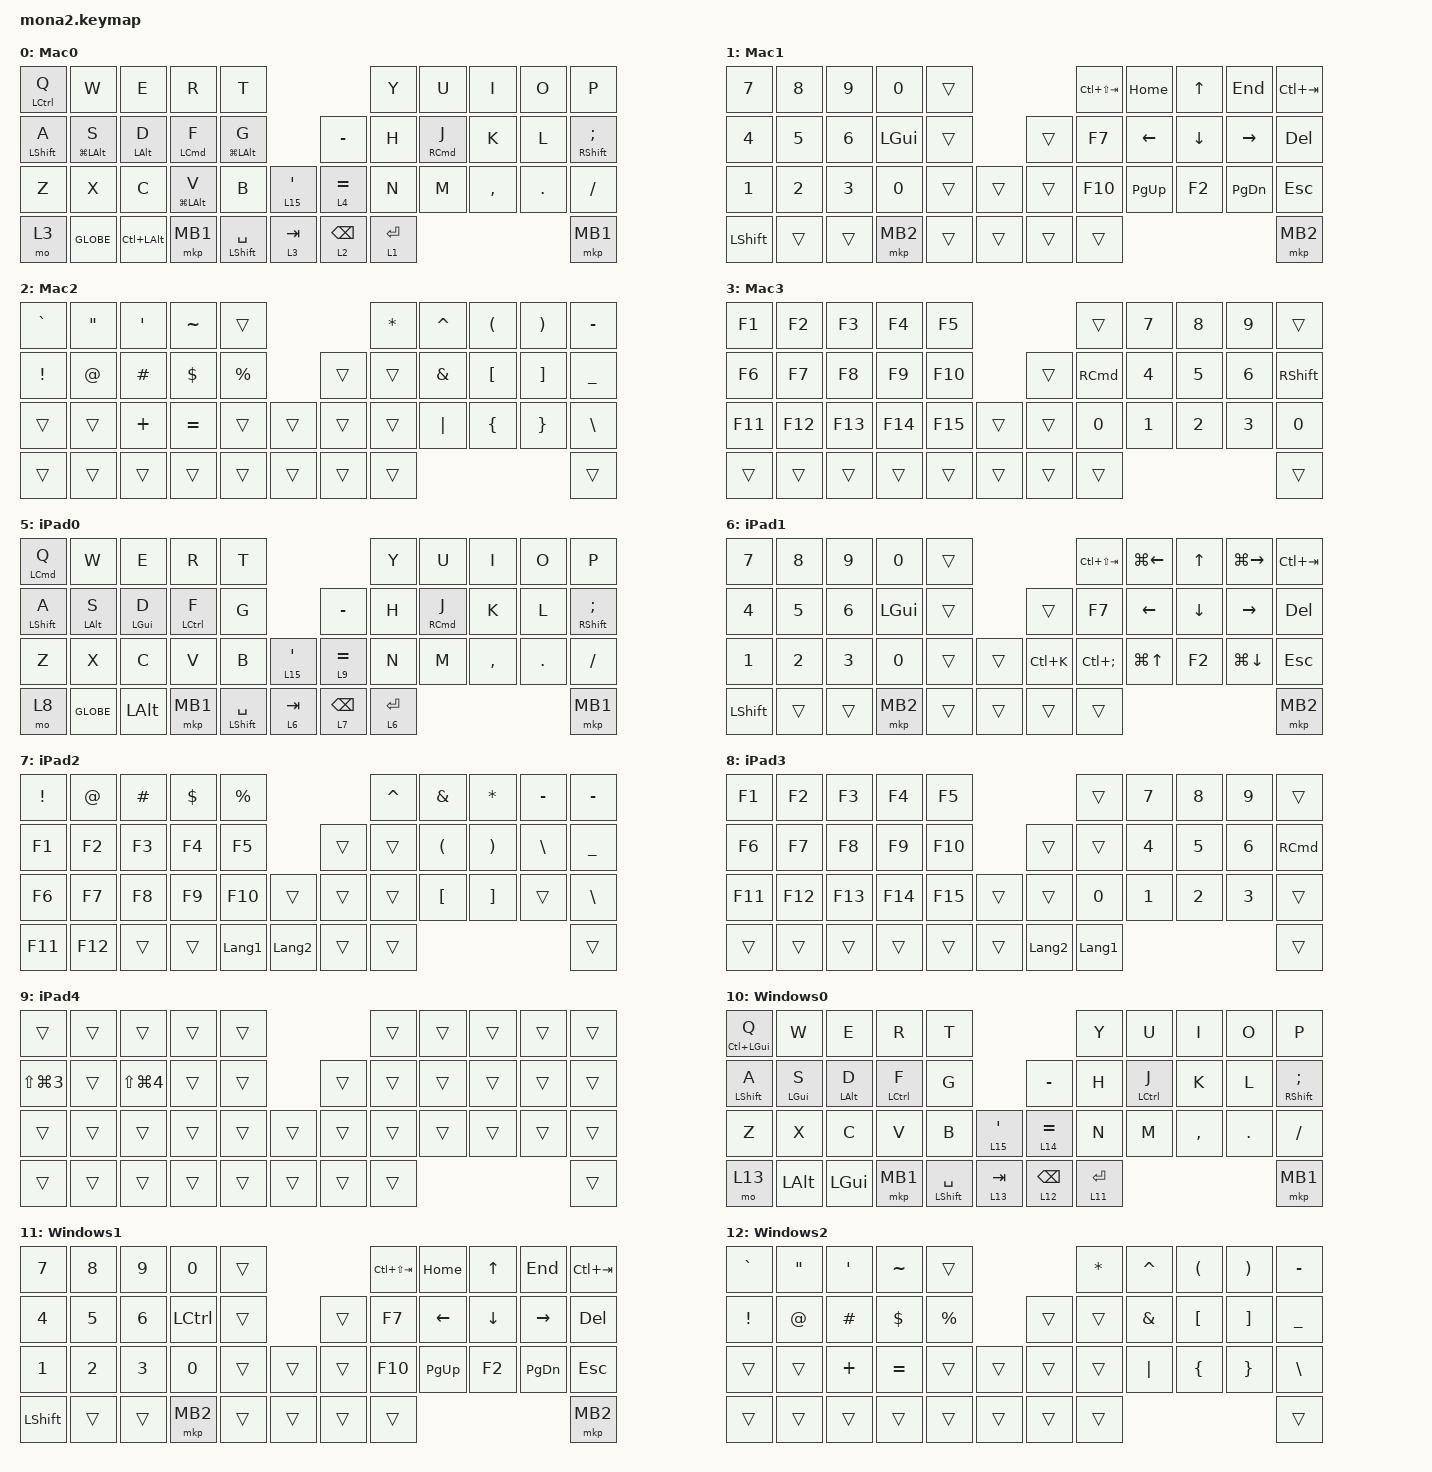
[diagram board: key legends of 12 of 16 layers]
#include <input/processors.dtsi>
#include <dt-bindings/zmk/input_transform.h>
#include <zephyr/dt-bindings/input/input-event-codes.h>

#define ZMK_POINTING_DEFAULT_SCRL_VAL 80

#include <behaviors.dtsi>
#include <dt-bindings/zmk/bt.h>
#include <dt-bindings/zmk/keys.h>
#include <dt-bindings/zmk/pointing.h>

#define MOUSE 6
#define SCROLL 7

&mt {
    flavor = "balanced";
    quick-tap-ms = <200>;
    tapping-term-ms = <180>;
    require-prior-idle-ms = <150>;
};

&lt {
    quick-tap-ms = <175>;
    tapping-term-ms = <165>;
};

/ {
    combos {
        compatible = "zmk,combos";

        alt_f4 {
            bindings = <&kp RA(F4)>;
            key-positions = <10 20>;
            timeout-ms = <201>;
            layers = <10>;
        };

        kana {
            bindings = <&kp LANG1>;
            key-positions = <17 18>;
            timeout-ms = <201>;
            layers = <10 0 5>;
        };

        ABC {
            bindings = <&kp LANG2>;
            key-positions = <13 12>;
            layers = <0 5 10>;
            timeout-ms = <201>;
        };
    };

    macros {
        to_layer_0: to_layer_0 {
            compatible = "zmk,behavior-macro-one-param";
            #binding-cells = <1>;
            bindings = <&to 0 &macro_param_1to1 &kp MACRO_PLACEHOLDER>;
            label = "TO_LAYER_0";
        };

        Bluetooth0: Bluetooth0 {
            compatible = "zmk,behavior-macro";
            #binding-cells = <0>;
            bindings =
                <&bt BT_SEL 0 &to 0 &bt BT_DISC 1 &bt BT_DISC 2 &bt BT_DISC 3 &bt BT_DISC 4>,
                <&macro_press>;

            label = "BLUETOOTH0";
        };

        Bluetooth1: Bluetooth1 {
            compatible = "zmk,behavior-macro";
            #binding-cells = <0>;
            bindings =
                <&bt BT_SEL 1 &to 5 &bt BT_DISC 0 &bt BT_DISC 2 &bt BT_DISC 3 &bt BT_DISC 4>,
                <&macro_press>;

            label = "BLUETOOTH1";
        };

        Bluetooth2: Bluetooth2 {
            compatible = "zmk,behavior-macro";
            #binding-cells = <0>;
            bindings =
                <&bt BT_SEL 2 &to 10 &bt BT_DISC 0 &bt BT_DISC 1 &bt BT_DISC 3 &bt BT_DISC 4>,
                <&macro_press>;

            label = "BLUETOOTH2";
        };

        Bluetooth3: Bluetooth3 {
            compatible = "zmk,behavior-macro";
            #binding-cells = <0>;
            bindings =
                <&bt BT_SEL 3 &to 10 &bt BT_DISC 0 &bt BT_DISC 1 &bt BT_DISC 2 &bt BT_DISC 4>,
                <&macro_press>;

            label = "BLUETOOTH3";
        };

        Bluetooth4: Bluetooth4 {
            compatible = "zmk,behavior-macro";
            #binding-cells = <0>;
            bindings =
                <&bt BT_SEL 4 &to 10 &bt BT_DISC 0 &bt BT_DISC 1 &bt BT_DISC 2 &bt BT_DISC 3>,
                <&macro_press>;

            label = "BLUETOOTH4";
        };

        mac_sleep: mac_sleep {
            compatible = "zmk,behavior-macro";
            #binding-cells = <0>;
            wait-ms = <30>;
            tap-ms = <40>;
            bindings =
                <&macro_press &kp LCTRL &kp LALT &kp LGUI>,
                <&macro_tap &kp S>,
                <&macro_release &kp LCTRL &kp LALT &kp LGUI>,
                <&macro_pause_for_release>;

            label = "MAC_SLEEP";
        };

        mac_shutdown: mac_shutdown {
            compatible = "zmk,behavior-macro";
            #binding-cells = <0>;
            wait-ms = <30>;
            tap-ms = <40>;
            bindings =
                <&macro_press &kp LCTRL &kp LALT &kp LGUI>,
                <&macro_tap &kp Q>,
                <&macro_release &kp LCTRL &kp LALT &kp LGUI>,
                <&macro_pause_for_release>;

            label = "MAC_SHUTDOWN";
        };
    };

    behaviors {
        lt_to_layer_0: lt_to_layer_0 {
            compatible = "zmk,behavior-hold-tap";
            label = "LAYER_TAP_TO_0";
            bindings = <&mo>, <&to_layer_0>;

            #binding-cells = <2>;
            tapping-term-ms = <200>;
        };

        win_alt_d: win_alt_d {
            compatible = "zmk,behavior-hold-tap";
            #binding-cells = <2>;
            flavor = "balanced";
            tapping-term-ms = <200>;
            quick-tap-ms = <200>;
            require-prior-idle-ms = <150>;
            bindings = <&kp>, <&kp>;

            hold-trigger-key-positions = <6 7 8 13 17 18 19 24 38 39 40>;
            hold-trigger-on-release;
        };

        win_alt_k: win_alt_k {
            compatible = "zmk,behavior-hold-tap";
            #binding-cells = <2>;
            flavor = "balanced";
            tapping-term-ms = <200>;
            quick-tap-ms = <200>;
            require-prior-idle-ms = <150>;
            bindings = <&kp>, <&kp>;

            hold-trigger-key-positions = <4 17 38 39 40>;
            hold-trigger-on-release;
        };

        f_left_mod: f_left_mod {
            compatible = "zmk,behavior-hold-tap";
            #binding-cells = <2>;
            flavor = "balanced";
            tapping-term-ms = <200>;
            quick-tap-ms = <200>;
            require-prior-idle-ms = <150>;
            bindings = <&kp>, <&kp>;

            hold-trigger-key-positions = <5 6 7 8 9 15 16 17 18 19 20 27 28 29 30 31 32 36 37 39 40 41>;
            hold-trigger-on-release;
        };

        s_left_mod: s_left_mod {
            compatible = "zmk,behavior-hold-tap";
            #binding-cells = <2>;
            flavor = "balanced";
            tapping-term-ms = <200>;
            quick-tap-ms = <200>;
            require-prior-idle-ms = <150>;
            bindings = <&kp>, <&kp>;

            hold-trigger-key-positions = <5 6 7 8 9 15 16 17 18 19 20 27 28 29 30 31 32 36 37 39 40 41>;
            hold-trigger-on-release;
        };

        j_right_mod: j_right_mod {
            compatible = "zmk,behavior-hold-tap";
            #binding-cells = <2>;
            flavor = "balanced";
            tapping-term-ms = <200>;
            quick-tap-ms = <200>;
            require-prior-idle-ms = <150>;
            bindings = <&kp>, <&kp>;

            hold-trigger-key-positions = <0 1 2 3 4 10 11 12 13 14 18 19 21 22 23 24 25 26 33 34 35 36 37 38>;
            hold-trigger-on-release;
        };

        shift_space: shift_space {
            compatible = "zmk,behavior-hold-tap";
            #binding-cells = <2>;
            flavor = "balanced";
            tapping-term-ms = <165>;
            quick-tap-ms = <0>;
            require-prior-idle-ms = <60>;
            bindings = <&kp>, <&kp>;
        };

        shift_a: shift_a {
            compatible = "zmk,behavior-hold-tap";
            #binding-cells = <2>;
            flavor = "balanced";
            tapping-term-ms = <180>;
            quick-tap-ms = <0>;
            require-prior-idle-ms = <0>;
            bindings = <&kp>, <&kp>;

            hold-trigger-key-positions = <0 13 30 31 32 36 37 38 40>;
            #hold-trigger-on-release;
        };

        enter_lt: enter_layer_tap {
            compatible = "zmk,behavior-hold-tap";
            #binding-cells = <2>;
            flavor = "balanced";
            tapping-term-ms = <165>;
            quick-tap-ms = <175>;
            require-prior-idle-ms = <0>;
            bindings = <&mo>, <&kp>;

            hold-trigger-key-positions = <0 1 2 3 5 6 7 8 9 10 11 12 13 16 17 18 19 20 21 22 23 24 27 28 29 30 31 32 36>;
        };

        ascii_slash: ascii_slash {
            compatible = "zmk,behavior-macro";
            #binding-cells = <0>;
            wait-ms = <30>;
            tap-ms = <20>;
            bindings = <&kp LANG2 &kp SLASH &kp LANG1>;
        };

        ascii_minus: ascii_minus {
            compatible = "zmk,behavior-macro";
            #binding-cells = <0>;
            wait-ms = <30>;
            tap-ms = <20>;
            bindings = <&kp LANG2 &kp MINUS &kp LANG1>;
        };

        bksp_lt_hp: backspace_layer_tap_hold_preferred {
            compatible = "zmk,behavior-hold-tap";
            #binding-cells = <2>;
            flavor = "balanced";
            tapping-term-ms = <165>;
            quick-tap-ms = <175>;
            bindings = <&mo>, <&kp>;

            #hold-while-undecided;
        };

        scroll_up_down: mouse_wheel_up_down {
            compatible = "zmk,behavior-sensor-rotate";
            #sensor-binding-cells = <0>;
            bindings = <&msc SCRL_UP>, <&msc SCRL_DOWN>;

            tap-ms = <20>;
        };

        mg_set_0: behavior_mg_set_0 {
            compatible = "zmk,behavior-mg-set-fixed";
            #binding-cells = <0>;
            display-name = "Mouse Gesture Key 0";
        };

        mg_set_1: behavior_mg_set_1 {
            compatible = "zmk,behavior-mg-set-fixed";
            #binding-cells = <0>;
            display-name = "Mouse Gesture Key 1";
        };

        mg_set_2: behavior_mg_set_2 {
            compatible = "zmk,behavior-mg-set-fixed";
            #binding-cells = <0>;
            display-name = "Mouse Gesture Key 2";
        };

    };

    keymap {
        compatible = "zmk,keymap";

        Mac0 {

            display-name = "Mac0";
            bindings = <
&mt LEFT_CONTROL Q     &kp W      &kp E                  &kp R                       &kp T                                                                          &kp Y              &kp U                         &kp I      &kp O    &kp P
&shift_a LEFT_SHIFT A  &s_left_mod LG(LEFT_ALT) S  &win_alt_d LEFT_ALT D  &f_left_mod LEFT_COMMAND F  &s_left_mod LG(LEFT_ALT) G  &kp MINUS  &kp H  &j_right_mod RIGHT_COMMAND J  &kp K  &kp L  &mt RIGHT_SHIFT SEMICOLON
&kp Z                  &kp X      &kp C                  &s_left_mod LG(LEFT_ALT) V  &kp B                          &lt 15 SINGLE_QUOTE    &lt 4 EQUAL              &kp N              &kp M                         &kp COMMA  &kp DOT  &kp SLASH
&mo 3  &kp GLOBE  &kp LC(LEFT_ALT)  &mkp MB1  &shift_space LEFT_SHIFT SPACE  &lt 3 TAB  &bksp_lt_hp 2 BACKSPACE  &enter_lt 1 ENTER  &mkp MB1
            >;

            sensor-bindings =
                <&scroll_up_down>,
                <&inc_dec_kp C_VOL_DN C_VOL_UP>;
        };

        Mac1 {

            display-name = "Mac1";
            bindings = <
&kp NUMBER_7    &kp NUMBER_8  &kp NUMBER_9  &kp NUMBER_0  &trans                    &kp LC(LS(TAB))  &kp HOME        &kp UP_ARROW    &kp END          &kp LC(TAB)
&kp NUMBER_4  &kp NUMBER_5  &kp NUMBER_6  &kp LEFT_GUI  &trans  &trans  &kp F7  &kp LEFT_ARROW  &kp DOWN_ARROW  &kp RIGHT_ARROW  &kp DELETE
&kp NUMBER_1  &kp NUMBER_2  &kp NUMBER_3  &kp NUMBER_0  &trans  &trans  &trans  &kp F10  &kp PAGE_UP  &kp F2  &kp PAGE_DOWN  &kp ESCAPE
&kp LEFT_SHIFT  &trans        &trans        &mkp MB2      &trans  &trans    &trans  &trans                                                            &mkp MB2
            >;

            sensor-bindings = <&inc_dec_kp LG(MINUS) LG(EQUAL)>;
        };

        Mac2 {

            display-name = "Mac2";
            bindings = <
&kp GRAVE        &kp DOUBLE_QUOTES  &kp SINGLE_QUOTE  &kp TILDE   &trans                         &kp ASTERISK  &kp CARET      &kp LEFT_PARENTHESIS  &kp RIGHT_PARENTHESIS  &kp MINUS
&kp EXCLAMATION  &kp AT_SIGN        &kp HASH          &kp DOLLAR  &kp PERCENT            &trans  &trans        &kp AMPERSAND  &kp LEFT_BRACKET      &kp RIGHT_BRACKET      &kp UNDERSCORE
&trans           &trans             &kp PLUS          &kp EQUAL   &trans       &trans    &trans  &trans        &kp PIPE       &kp LEFT_BRACE        &kp RIGHT_BRACE        &kp BACKSLASH
&trans           &trans             &trans            &trans      &trans       &trans    &trans  &trans                                                                    &trans
            >;

            sensor-bindings = <&inc_dec_kp C_VOLUME_DOWN C_VOLUME_UP>;
        };

        Mac3 {

            display-name = "Mac3";
            bindings = <
&kp F1  &kp F2  &kp F3  &kp F4  &kp F5  &trans  &kp NUMBER_7  &kp NUMBER_8  &kp NUMBER_9  &trans
&kp F6  &kp F7  &kp F8  &kp F9  &kp F10  &trans  &kp RIGHT_COMMAND  &kp NUMBER_4  &kp NUMBER_5  &kp NUMBER_6  &kp RIGHT_SHIFT
&kp F11  &kp F12  &kp F13  &kp F14  &kp F15  &trans  &trans  &kp NUMBER_0  &kp NUMBER_1  &kp NUMBER_2  &kp NUMBER_3  &kp N0
&trans  &trans   &trans   &trans   &trans  &trans    &trans  &trans                                                       &trans
            >;
        };

        Mac4 {

            display-name = "Mac4";
            bindings = <
&trans                &trans                &trans                &trans                &trans                                                          &trans          &trans           &trans  &trans  &trans
&kp LS(LG(NUMBER_3))  &kp LC(LS(LG(N3)))    &kp LS(LG(NUMBER_4))  &kp LC(LS(LG(N4)))    &kp LS(LG(NUMBER_5))                       &trans               &trans          &mac_shutdown    &trans  &trans  &trans
&kp LC(LG(Q))         &mac_sleep            &trans                &trans                &trans                 &trans      &trans  &trans               &trans          &trans           &trans  &trans
&trans                &trans                &trans                &trans                &trans                 &trans      &trans  &trans                                                                &trans
            >;
        };

        iPad0 {

            display-name = "iPad0";
            bindings = <
&mt LEFT_COMMAND Q  &kp W      &kp E                  &kp R                &kp T                                                                  &kp Y        &kp U                         &kp I      &kp O    &kp P
&mt LEFT_SHIFT A  &s_left_mod LEFT_ALT S  &win_alt_d LEFT_GUI D  &f_left_mod LCTRL F  &kp G  &kp MINUS  &kp H  &j_right_mod RIGHT_COMMAND J  &kp K  &kp L  &mt RIGHT_SHIFT SEMICOLON
&kp Z               &kp X      &kp C                  &kp V                &kp B                          &lt 15 SINGLE_QUOTE    &lt 9 EQUAL      &kp N        &kp M                         &kp COMMA  &kp DOT  &kp SLASH
&mo 8               &kp GLOBE  &kp LEFT_ALT           &mkp MB1             &shift_space LEFT_SHIFT SPACE  &lt 6 TAB              &lt 7 BACKSPACE  &lt 6 ENTER                                                    &mkp MB1
            >;

            sensor-bindings =
                <&scroll_up_down>,
                <&inc_dec_kp C_VOL_DN C_VOL_UP>;
        };

        iPad1 {

            display-name = "iPad1";
            bindings = <
&kp NUMBER_7    &kp NUMBER_8  &kp NUMBER_9  &kp NUMBER_0  &trans                       &kp LC(LS(TAB))    &kp LG(LEFT)      &kp UP_ARROW    &kp LG(RIGHT)       &kp LC(TAB)
&kp NUMBER_4  &kp NUMBER_5  &kp NUMBER_6  &kp LEFT_GUI  &trans  &trans  &kp F7  &kp LEFT_ARROW  &kp DOWN_ARROW  &kp RIGHT_ARROW  &kp DELETE
&kp NUMBER_1    &kp NUMBER_2  &kp NUMBER_3  &kp NUMBER_0  &trans  &trans    &kp LC(K)  &kp LC(SEMICOLON)  &kp LG(UP_ARROW)  &kp F2          &kp LG(DOWN_ARROW)  &kp ESCAPE
&kp LEFT_SHIFT  &trans        &trans        &mkp MB2      &trans  &trans    &trans     &trans                                                                   &mkp MB2
            >;

            sensor-bindings = <&inc_dec_kp LG(MINUS) LG(EQUAL)>;
        };

        iPad2 {

            display-name = "iPad2";
            bindings = <
&kp EXCLAMATION  &kp AT_SIGN  &kp HASH  &kp DOLLAR  &kp PERCENT  &kp CARET  &kp AMPERSAND  &kp ASTRK  &kp MINUS  &kp MINUS
&kp F1  &kp F2  &kp F3  &kp F4  &kp F5  &trans  &trans  &kp LEFT_PARENTHESIS  &kp RIGHT_PARENTHESIS  &kp BACKSLASH  &kp UNDERSCORE
&kp F6  &kp F7  &kp F8  &kp F9  &kp F10  &trans  &trans  &trans  &kp LEFT_BRACKET  &kp RIGHT_BRACKET  &trans  &kp BACKSLASH
&kp F11          &kp F12      &trans    &trans      &kp LANGUAGE_1  &kp LANGUAGE_2    &trans  &trans                                                                 &trans
            >;

            sensor-bindings = <&inc_dec_kp C_VOLUME_DOWN C_VOLUME_UP>;
        };

        iPad3 {

            display-name = "iPad3";
            bindings = <
&kp F1  &kp F2  &kp F3  &kp F4  &kp F5  &trans  &kp NUMBER_7  &kp NUMBER_8  &kp NUMBER_9  &trans
&kp F6  &kp F7  &kp F8  &kp F9  &kp F10  &trans  &trans  &kp NUMBER_4  &kp NUMBER_5  &kp NUMBER_6  &kp RIGHT_COMMAND
&kp F11  &kp F12  &kp F13  &kp F14  &kp F15  &trans  &trans  &kp NUMBER_0  &kp NUMBER_1  &kp NUMBER_2  &kp NUMBER_3  &trans
&trans  &trans  &trans  &trans  &trans  &trans    &kp LANGUAGE_2  &kp LANGUAGE_1                                            &trans
            >;
        };

        iPad4 {

            display-name = "iPad4";
            bindings = <
&trans                &trans     &trans                &trans     &trans                                                &trans     &trans     &trans     &trans     &trans
&kp LS(LG(NUMBER_3))  &trans     &kp LS(LG(NUMBER_4))  &trans     &trans                              &trans            &trans     &trans     &trans     &trans     &trans
&trans                &trans     &trans                &trans     &trans          &trans      &trans  &trans            &trans     &trans     &trans     &trans
&trans                &trans     &trans                &trans     &trans          &trans      &trans  &trans                                                        &trans
            >;
        };

        Windows0 {

            display-name = "Windows0";
            bindings = <
&mt LC(LGUI) Q                  &kp W         &kp E                  &kp R                &kp T                                                                           &kp Y              &kp U                 &kp I      &kp O    &kp P
&shift_a LEFT_SHIFT A  &s_left_mod LEFT_GUI S  &win_alt_d LEFT_ALT D  &f_left_mod LCTRL F  &kp G  &kp MINUS  &kp H  &j_right_mod LCTRL J  &kp K  &kp L  &mt RIGHT_SHIFT SEMICOLON
&kp Z                  &kp X         &kp C                  &kp V                &kp B                          &lt 15 SINGLE_QUOTE    &lt 14 EQUAL              &kp N              &kp M                 &kp COMMA  &kp DOT  &kp SLASH
&mo 13                 &kp LEFT_ALT  &kp LEFT_GUI           &mkp MB1             &shift_space LEFT_SHIFT SPACE  &lt 13 TAB             &bksp_lt_hp 12 BACKSPACE  &enter_lt 11 ENTER                                            &mkp MB1
            >;

            sensor-bindings = <&scroll_up_down>;
        };

        Windows1 {

            display-name = "Windows1";
            bindings = <
&kp NUMBER_7    &kp NUMBER_8  &kp NUMBER_9  &kp NUMBER_0  &trans                    &kp LC(LS(TAB))  &kp HOME        &kp UP_ARROW    &kp END          &kp LC(TAB)
&kp NUMBER_4  &kp NUMBER_5  &kp NUMBER_6  &kp LCTRL  &trans  &trans  &kp F7  &kp LEFT_ARROW  &kp DOWN_ARROW  &kp RIGHT_ARROW  &kp DELETE
&kp NUMBER_1  &kp NUMBER_2  &kp NUMBER_3  &kp NUMBER_0  &trans  &trans  &trans  &kp F10  &kp PAGE_UP  &kp F2  &kp PAGE_DOWN  &kp ESCAPE
&kp LEFT_SHIFT  &trans        &trans        &mkp MB2      &trans  &trans    &trans  &trans                                                            &mkp MB2
            >;

            sensor-bindings = <&inc_dec_kp LC(MINUS) LC(PLUS)>;
        };

        Windows2 {

            display-name = "Windows2";
            bindings = <
&kp GRAVE        &kp DOUBLE_QUOTES  &kp SINGLE_QUOTE  &kp TILDE   &trans                         &kp ASTERISK  &kp CARET      &kp LEFT_PARENTHESIS  &kp RIGHT_PARENTHESIS  &kp MINUS
&kp EXCLAMATION  &kp AT_SIGN        &kp HASH          &kp DOLLAR  &kp PERCENT            &trans  &trans        &kp AMPERSAND  &kp LEFT_BRACKET      &kp RIGHT_BRACKET      &kp UNDERSCORE
&trans           &trans             &kp PLUS          &kp EQUAL   &trans       &trans    &trans  &trans        &kp PIPE       &kp LEFT_BRACE        &kp RIGHT_BRACE        &kp BACKSLASH
&trans           &trans             &trans            &trans      &trans       &trans    &trans  &trans                                                                    &trans
            >;

            sensor-bindings = <&inc_dec_kp C_VOLUME_DOWN C_VOLUME_UP>;
        };

        Windows3 {

            display-name = "Windows3";
            bindings = <
&kp F1  &kp F2  &kp F3  &kp F4  &kp F5  &trans  &kp NUMBER_7  &kp NUMBER_8  &kp NUMBER_9  &trans
&kp F6  &kp F7  &kp F8  &kp F9  &kp F10  &trans  &kp RCTRL  &kp NUMBER_4  &kp NUMBER_5  &kp NUMBER_6  &kp RIGHT_SHIFT
&kp F11  &kp F12  &kp F13  &kp F14  &kp F15  &trans  &trans  &kp NUMBER_0  &kp NUMBER_1  &kp NUMBER_2  &kp NUMBER_3  &kp NUMBER_0
&trans  &trans   &trans   &trans   &trans  &trans    &trans  &trans                                                  &trans
            >;
        };

        Windows4 {

            display-name = "Windows4";
            bindings = <
&trans        &trans        &trans        &trans        &trans                                                &trans          &trans          &trans  &trans  &trans
&trans  &trans  &trans  &kp LG(LS(S))  &trans  &trans  &trans  &kp C_POWER  &trans  &trans  &trans
&kp LG(L)     &kp C_SLEEP   &trans        &trans        &trans           &trans      &trans  &trans           &trans          &trans          &trans  &trans
&trans        &trans        &trans        &trans        &trans           &trans      &trans  &trans                                                          &trans
            >;
        };

        Bluetooth {

            display-name = "Bluetooth";
            bindings = <
&trans  &trans  &trans  &trans  &trans                         &trans  &trans       &trans       &trans       &Bluetooth4
&trans  &trans  &trans  &trans  &trans            &trans       &studio_unlock  &Bluetooth0  &Bluetooth1  &Bluetooth2  &Bluetooth3
&trans  &trans  &trans  &trans  &trans  &trans            &bootloader  &trans          &trans       &trans       &trans       &bt BT_CLR
&trans  &trans  &trans  &trans  &trans  &trans           &trans       &trans                                         &bt BT_CLR_ALL
            >;

            sensor-bindings = <&scroll_up_down>;
        };
    };
};
